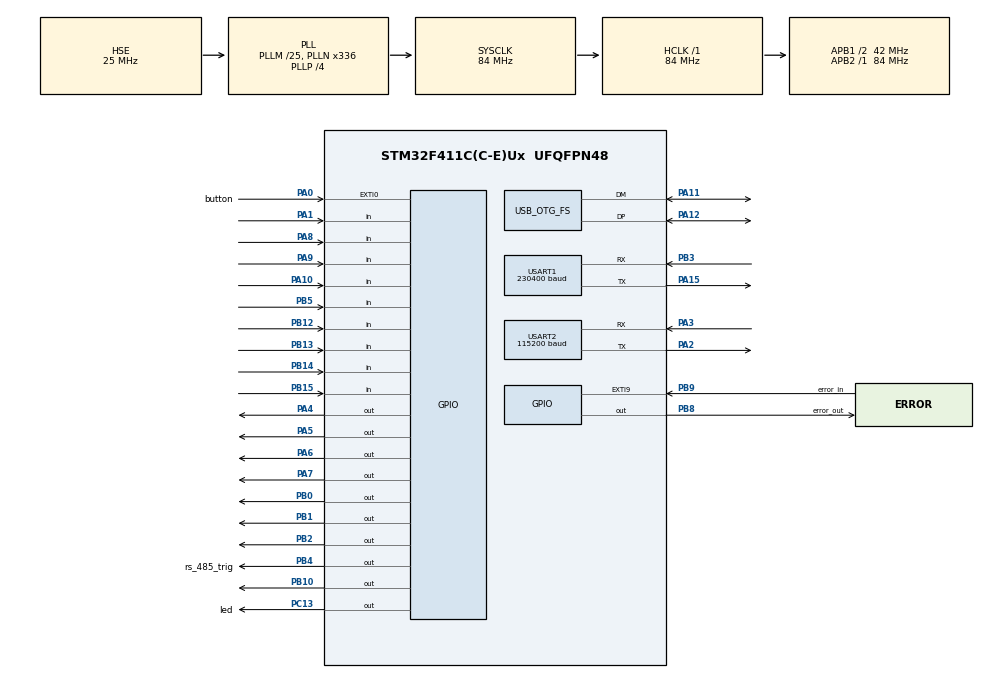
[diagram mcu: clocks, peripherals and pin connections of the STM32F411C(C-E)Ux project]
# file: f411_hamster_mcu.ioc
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Mcu.Family=STM32F4
Mcu.Name=STM32F411C(C-E)Ux
Mcu.Package=UFQFPN48
NVIC.EXTI0_IRQn=true\:0\:0\:false\:false\:true\:true\:true\:true
NVIC.EXTI9_5_IRQn=true\:0\:0\:false\:false\:true\:true\:true\:true
NVIC.OTG_FS_IRQn=true\:0\:0\:false\:false\:true\:false\:true\:true
NVIC.PriorityGroup=NVIC_PRIORITYGROUP_4
NVIC.TIM3_IRQn=true\:0\:0\:false\:false\:true\:true\:true\:true
NVIC.USART1_IRQn=true\:0\:0\:false\:false\:true\:true\:true\:true
NVIC.USART2_IRQn=true\:0\:0\:false\:false\:true\:true\:true\:true
PA0-WKUP.GPIO_Label=button
PA0-WKUP.GPIO_PuPd=GPIO_PULLUP
PA0-WKUP.Signal=GPXTI0
PA1.Signal=GPIO_Input
PA10.Signal=GPIO_Input
PA11.Mode=Device_Only
PA11.Signal=USB_OTG_FS_DM
PA12.Mode=Device_Only
PA12.Signal=USB_OTG_FS_DP
PA13.Mode=Serial_Wire
PA13.Signal=SYS_JTMS-SWDIO
PA14.Mode=Serial_Wire
PA14.Signal=SYS_JTCK-SWCLK
PA15.Mode=Asynchronous
PA15.Signal=USART1_TX
PA2.Mode=Asynchronous
PA2.Signal=USART2_TX
PA3.Mode=Asynchronous
PA3.Signal=USART2_RX
PA4.Signal=GPIO_Output
PA5.Signal=GPIO_Output
PA6.Signal=GPIO_Output
PA7.Signal=GPIO_Output
PA8.Signal=GPIO_Input
PA9.Signal=GPIO_Input
PB0.Signal=GPIO_Output
PB1.Signal=GPIO_Output
PB10.Signal=GPIO_Output
PB12.Signal=GPIO_Input
PB13.Signal=GPIO_Input
PB14.Signal=GPIO_Input
PB15.Signal=GPIO_Input
PB2.Signal=GPIO_Output
PB3.Mode=Asynchronous
PB3.Signal=USART1_RX
PB4.GPIO_Label=rs_485_trig 
PB4.GPIO_Speed=GPIO_SPEED_FREQ_HIGH
PB4.Signal=GPIO_Output
PB5.Signal=GPIO_Input
PB8.GPIO_Label=error_out
PB8.Signal=GPIO_Output
PB9.GPIO_Label=error_in
PB9.GPIO_PuPd=GPIO_PULLUP
PB9.Signal=GPXTI9
PC13-ANTI_TAMP.GPIO_Label=led
PC13-ANTI_TAMP.Signal=GPIO_Output
PC14-OSC32_IN.Mode=LSE-External-Oscillator
PC14-OSC32_IN.Signal=RCC_OSC32_IN
PC15-OSC32_OUT.Mode=LSE-External-Oscillator
PC15-OSC32_OUT.Signal=RCC_OSC32_OUT
PH0\ -\ OSC_IN.Mode=HSE-External-Oscillator
PH0\ -\ OSC_IN.Signal=RCC_OSC_IN
PH1\ -\ OSC_OUT.Mode=HSE-External-Oscillator
PH1\ -\ OSC_OUT.Signal=RCC_OSC_OUT
ProjectManager.HeapSize=0x200
ProjectManager.StackSize=0x400
ProjectManager.TargetToolchain=STM32CubeIDE
RCC.48MHZClocksFreq_Value=48000000
RCC.AHBFreq_Value=84000000
RCC.APB1CLKDivider=RCC_HCLK_DIV2
RCC.APB1Freq_Value=42000000
RCC.APB1TimFreq_Value=84000000
RCC.APB2Freq_Value=84000000
RCC.APB2TimFreq_Value=84000000
RCC.CortexFreq_Value=84000000
RCC.HCLKFreq_Value=84000000
RCC.HSE_VALUE=25000000
RCC.HSI_VALUE=16000000
RCC.PLLM=25
RCC.PLLN=336
RCC.PLLP=RCC_PLLP_DIV4
RCC.PLLQ=7
RCC.SYSCLKFreq_VALUE=84000000
RCC.SYSCLKSource=RCC_SYSCLKSOURCE_PLLCLK
RCC.VCOOutputFreq_Value=336000000
USART1.BaudRate=230400
USART1.VirtualMode=VM_ASYNC
USART2.BaudRate=115200
USART2.VirtualMode=VM_ASYNC
USB_DEVICE.CLASS_NAME_FS=CDC
USB_DEVICE.MANUFACTURER_STRING=graffit robotics
USB_DEVICE.PRODUCT_STRING_CDC_FS=hamster controller
USB_DEVICE.VirtualMode=Cdc
USB_DEVICE.VirtualModeFS=Cdc_FS
USB_OTG_FS.VirtualMode=Device_Only
VP_TIM3_VS_ClockSourceINT.Mode=Internal
VP_USB_DEVICE_VS_USB_DEVICE_CDC_FS.Mode=CDC_FS
board=custom

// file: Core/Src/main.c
/* USER CODE BEGIN Header */
/**
 ******************************************************************************
 * @file           : main.c
 * @brief          : Main program body
 ******************************************************************************
 * @attention
 *
 * Copyright (c) 2023 STMicroelectronics.
 * All rights reserved.
 *
 * This software is licensed under terms that can be found in the LICENSE file
 * in the root directory of this software component.
 * If no LICENSE file comes with this software, it is provided AS-IS.
 *
 ******************************************************************************
 */
/* USER CODE END Header */
#include "main.h"
#include "usb_device.h"

/* USER CODE BEGIN Includes */
#include "cmd_tracer/cmd_tracer.h"
/* USER CODE END Includes */

TIM_HandleTypeDef htim3;

UART_HandleTypeDef huart1;
UART_HandleTypeDef huart2;

/* USER CODE BEGIN PV */
CMD_trace cmd[3];
/* USER CODE END PV */

void SystemClock_Config(void);
static void MX_GPIO_Init(void);
static void MX_USART2_UART_Init(void);
static void MX_USART1_UART_Init(void);
static void MX_TIM3_Init(void);

int main(void) {

	/* MCU Configuration--------------------------------------------------------*/

	/* Reset of all peripherals, Initializes the Flash interface and the Systick. */
	HAL_Init();

	/* Configure the system clock */
	SystemClock_Config();

	/* Initialize all configured peripherals */
	MX_GPIO_Init();
	MX_USB_DEVICE_Init();
	MX_USART2_UART_Init();
	MX_USART1_UART_Init();
	MX_TIM3_Init();
	/* USER CODE BEGIN 2 */
	cmdInit();
	/* USER CODE END 2 */

	/* Infinite loop */
	while (1) {

	}
}

void SystemClock_Config(void) {
	RCC_OscInitTypeDef RCC_OscInitStruct = { 0 };
	RCC_ClkInitTypeDef RCC_ClkInitStruct = { 0 };

	/** Configure the main internal regulator output voltage
	 */
	__HAL_RCC_PWR_CLK_ENABLE();
	__HAL_PWR_VOLTAGESCALING_CONFIG(PWR_REGULATOR_VOLTAGE_SCALE1);

	/** Initializes the RCC Oscillators according to the specified parameters
	 * in the RCC_OscInitTypeDef structure.
	 */
	RCC_OscInitStruct.OscillatorType = RCC_OSCILLATORTYPE_HSE;
	RCC_OscInitStruct.HSEState = RCC_HSE_ON;
	RCC_OscInitStruct.PLL.PLLState = RCC_PLL_ON;
	RCC_OscInitStruct.PLL.PLLSource = RCC_PLLSOURCE_HSE;
	RCC_OscInitStruct.PLL.PLLM = 25;
	RCC_OscInitStruct.PLL.PLLN = 336;
	RCC_OscInitStruct.PLL.PLLP = RCC_PLLP_DIV4;
	RCC_OscInitStruct.PLL.PLLQ = 7;
	if (HAL_RCC_OscConfig(&RCC_OscInitStruct) != HAL_OK) {
		Error_Handler();
	}

	/** Initializes the CPU, AHB and APB buses clocks
	 */
	RCC_ClkInitStruct.ClockType = RCC_CLOCKTYPE_HCLK | RCC_CLOCKTYPE_SYSCLK
			| RCC_CLOCKTYPE_PCLK1 | RCC_CLOCKTYPE_PCLK2;
	RCC_ClkInitStruct.SYSCLKSource = RCC_SYSCLKSOURCE_PLLCLK;
	RCC_ClkInitStruct.AHBCLKDivider = RCC_SYSCLK_DIV1;
	RCC_ClkInitStruct.APB1CLKDivider = RCC_HCLK_DIV2;
	RCC_ClkInitStruct.APB2CLKDivider = RCC_HCLK_DIV1;

	if (HAL_RCC_ClockConfig(&RCC_ClkInitStruct, FLASH_LATENCY_2) != HAL_OK) {
		Error_Handler();
	}
}

static void MX_TIM3_Init(void) {

	TIM_ClockConfigTypeDef sClockSourceConfig = { 0 };
	TIM_MasterConfigTypeDef sMasterConfig = { 0 };

	htim3.Instance = TIM3;
	htim3.Init.Prescaler = 0;
	htim3.Init.CounterMode = TIM_COUNTERMODE_UP;
	htim3.Init.Period = 65535;
	htim3.Init.ClockDivision = TIM_CLOCKDIVISION_DIV1;
	htim3.Init.AutoReloadPreload = TIM_AUTORELOAD_PRELOAD_DISABLE;
	if (HAL_TIM_Base_Init(&htim3) != HAL_OK) {
		Error_Handler();
	}
	sClockSourceConfig.ClockSource = TIM_CLOCKSOURCE_INTERNAL;
	if (HAL_TIM_ConfigClockSource(&htim3, &sClockSourceConfig) != HAL_OK) {
		Error_Handler();
	}
	sMasterConfig.MasterOutputTrigger = TIM_TRGO_RESET;
	sMasterConfig.MasterSlaveMode = TIM_MASTERSLAVEMODE_DISABLE;
	if (HAL_TIMEx_MasterConfigSynchronization(&htim3, &sMasterConfig)
			!= HAL_OK) {
		Error_Handler();
	}

}

static void MX_USART1_UART_Init(void) {

	huart1.Instance = USART1;
	huart1.Init.BaudRate = 230400;
	huart1.Init.WordLength = UART_WORDLENGTH_8B;
	huart1.Init.StopBits = UART_STOPBITS_1;
	huart1.Init.Parity = UART_PARITY_NONE;
	huart1.Init.Mode = UART_MODE_TX_RX;
	huart1.Init.HwFlowCtl = UART_HWCONTROL_NONE;
	huart1.Init.OverSampling = UART_OVERSAMPLING_16;
	if (HAL_UART_Init(&huart1) != HAL_OK) {
		Error_Handler();
	}

}

static void MX_USART2_UART_Init(void) {

	huart2.Instance = USART2;
	huart2.Init.BaudRate = 115200;
	huart2.Init.WordLength = UART_WORDLENGTH_8B;
	huart2.Init.StopBits = UART_STOPBITS_1;
	huart2.Init.Parity = UART_PARITY_NONE;
	huart2.Init.Mode = UART_MODE_TX_RX;
	huart2.Init.HwFlowCtl = UART_HWCONTROL_NONE;
	huart2.Init.OverSampling = UART_OVERSAMPLING_16;
	if (HAL_UART_Init(&huart2) != HAL_OK) {
		Error_Handler();
	}
	/* USER CODE BEGIN USART2_Init 2 */
	USART2->CR1 |= USART_CR1_RXNEIE;

	/* USER CODE END USART2_Init 2 */

}

static void MX_GPIO_Init(void) {
	GPIO_InitTypeDef GPIO_InitStruct = { 0 };

	/* GPIO Ports Clock Enable */
	__HAL_RCC_GPIOC_CLK_ENABLE();
	__HAL_RCC_GPIOH_CLK_ENABLE();
	__HAL_RCC_GPIOA_CLK_ENABLE();
	__HAL_RCC_GPIOB_CLK_ENABLE();

	/*Configure GPIO pin Output Level */
	HAL_GPIO_WritePin(led_GPIO_Port, led_Pin, GPIO_PIN_RESET);

	/*Configure GPIO pin Output Level */
	HAL_GPIO_WritePin(GPIOA, GPIO_PIN_4 | GPIO_PIN_5 | GPIO_PIN_6 | GPIO_PIN_7,
			GPIO_PIN_RESET);

	/*Configure GPIO pin Output Level */
	HAL_GPIO_WritePin(GPIOB,
			GPIO_PIN_0 | GPIO_PIN_1 | GPIO_PIN_2 | GPIO_PIN_10 | rs_485_trig_Pin
					| error_out_Pin, GPIO_PIN_RESET);

	/*Configure GPIO pin : led_Pin */
	GPIO_InitStruct.Pin = led_Pin;
	GPIO_InitStruct.Mode = GPIO_MODE_OUTPUT_PP;
	GPIO_InitStruct.Pull = GPIO_NOPULL;
	GPIO_InitStruct.Speed = GPIO_SPEED_FREQ_LOW;
	HAL_GPIO_Init(led_GPIO_Port, &GPIO_InitStruct);

	/*Configure GPIO pin : button_Pin */
	GPIO_InitStruct.Pin = button_Pin;
	GPIO_InitStruct.Mode = GPIO_MODE_IT_RISING;
	GPIO_InitStruct.Pull = GPIO_PULLUP;
	HAL_GPIO_Init(button_GPIO_Port, &GPIO_InitStruct);

	/*Configure GPIO pins : PA1 PA8 PA9 PA10 */
	GPIO_InitStruct.Pin = GPIO_PIN_1 | GPIO_PIN_8 | GPIO_PIN_9 | GPIO_PIN_10;
	GPIO_InitStruct.Mode = GPIO_MODE_INPUT;
	GPIO_InitStruct.Pull = GPIO_NOPULL;
	HAL_GPIO_Init(GPIOA, &GPIO_InitStruct);

	/*Configure GPIO pins : PA4 PA5 PA6 PA7 */
	GPIO_InitStruct.Pin = GPIO_PIN_4 | GPIO_PIN_5 | GPIO_PIN_6 | GPIO_PIN_7;
	GPIO_InitStruct.Mode = GPIO_MODE_OUTPUT_PP;
	GPIO_InitStruct.Pull = GPIO_NOPULL;
	GPIO_InitStruct.Speed = GPIO_SPEED_FREQ_LOW;
	HAL_GPIO_Init(GPIOA, &GPIO_InitStruct);

	/*Configure GPIO pins : PB0 PB1 PB2 PB10
	 error_out_Pin */
	GPIO_InitStruct.Pin = GPIO_PIN_0 | GPIO_PIN_1 | GPIO_PIN_2 | GPIO_PIN_10
			| error_out_Pin;
	GPIO_InitStruct.Mode = GPIO_MODE_OUTPUT_PP;
	GPIO_InitStruct.Pull = GPIO_NOPULL;
	GPIO_InitStruct.Speed = GPIO_SPEED_FREQ_LOW;
	HAL_GPIO_Init(GPIOB, &GPIO_InitStruct);

	/*Configure GPIO pins : PB12 PB13 PB14 PB15
	 PB5 */
	GPIO_InitStruct.Pin = GPIO_PIN_12 | GPIO_PIN_13 | GPIO_PIN_14 | GPIO_PIN_15
			| GPIO_PIN_5;
	GPIO_InitStruct.Mode = GPIO_MODE_INPUT;
	GPIO_InitStruct.Pull = GPIO_NOPULL;
	HAL_GPIO_Init(GPIOB, &GPIO_InitStruct);

	/*Configure GPIO pin : rs_485_trig_Pin */
	GPIO_InitStruct.Pin = rs_485_trig_Pin;
	GPIO_InitStruct.Mode = GPIO_MODE_OUTPUT_PP;
	GPIO_InitStruct.Pull = GPIO_NOPULL;
	GPIO_InitStruct.Speed = GPIO_SPEED_FREQ_HIGH;
	HAL_GPIO_Init(rs_485_trig_GPIO_Port, &GPIO_InitStruct);

	/*Configure GPIO pin : error_in_Pin */
	GPIO_InitStruct.Pin = error_in_Pin;
	GPIO_InitStruct.Mode = GPIO_MODE_IT_RISING;
	GPIO_InitStruct.Pull = GPIO_PULLUP;
	HAL_GPIO_Init(error_in_GPIO_Port, &GPIO_InitStruct);

	/* EXTI interrupt init*/
	HAL_NVIC_SetPriority(EXTI0_IRQn, 0, 0);
	HAL_NVIC_EnableIRQ(EXTI0_IRQn);

	HAL_NVIC_SetPriority(EXTI9_5_IRQn, 0, 0);
	HAL_NVIC_EnableIRQ(EXTI9_5_IRQn);

}

void Error_Handler(void) {
	__disable_irq();
	while (1) {
	}
}
